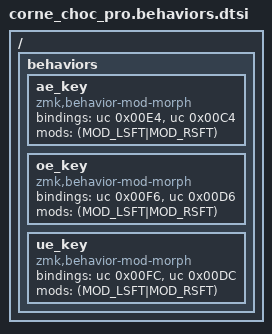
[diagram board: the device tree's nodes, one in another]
/ {
    behaviors {
        ae_key: ae_key {
            compatible = "zmk,behavior-mod-morph";
            #binding-cells = <0>;
            bindings = <&uc 0x00E4>, <&uc 0x00C4>; /* ä / Ä */
            mods = <(MOD_LSFT|MOD_RSFT)>;
        };

        oe_key: oe_key {
            compatible = "zmk,behavior-mod-morph";
            #binding-cells = <0>;
            bindings = <&uc 0x00F6>, <&uc 0x00D6>; /* ö / Ö */
            mods = <(MOD_LSFT|MOD_RSFT)>;
        };

        ue_key: ue_key {
            compatible = "zmk,behavior-mod-morph";
            #binding-cells = <0>;
            bindings = <&uc 0x00FC>, <&uc 0x00DC>; /* ü / Ü */
            mods = <(MOD_LSFT|MOD_RSFT)>;
        };
    };
};
